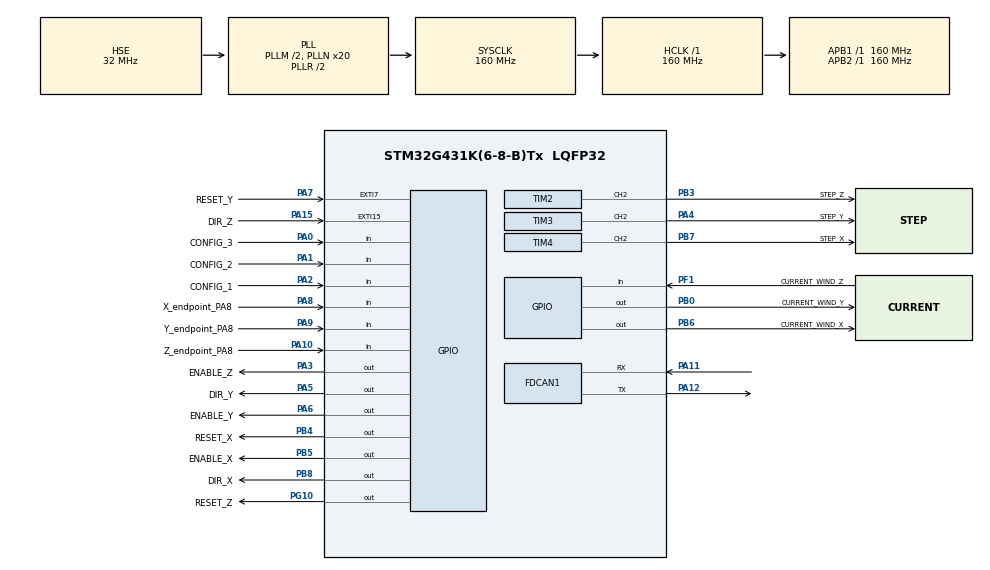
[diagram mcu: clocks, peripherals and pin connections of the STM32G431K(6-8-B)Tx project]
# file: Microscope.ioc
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FDCAN1.DataPrescaler=20
FDCAN1.DataSyncJumpWidth=3
FDCAN1.DataTimeSeg1=11
FDCAN1.DataTimeSeg2=14
FDCAN1.NominalPrescaler=20
FDCAN1.NominalSyncJumpWidth=3
FDCAN1.NominalTimeSeg1=11
FDCAN1.NominalTimeSeg2=4
Mcu.Family=STM32G4
Mcu.Name=STM32G431K(6-8-B)Tx
Mcu.Package=LQFP32
NVIC.EXTI15_10_IRQn=true\:0\:0\:false\:false\:true\:true\:true
NVIC.EXTI9_5_IRQn=true\:0\:0\:false\:false\:true\:true\:true
NVIC.FDCAN1_IT0_IRQn=true\:0\:0\:false\:false\:true\:true\:true
NVIC.PriorityGroup=NVIC_PRIORITYGROUP_4
NVIC.TIM1_UP_TIM16_IRQn=true\:0\:0\:false\:false\:true\:true\:true
NVIC.TIM2_IRQn=true\:0\:0\:false\:false\:true\:true\:true
NVIC.TIM3_IRQn=true\:0\:0\:false\:false\:true\:true\:true
NVIC.TIM4_IRQn=true\:0\:0\:false\:false\:true\:true\:true
NVIC.TIM7_IRQn=true\:0\:0\:false\:false\:true\:true\:true
PA0.GPIO_Label=CONFIG_3
PA0.GPIO_PuPd=GPIO_PULLDOWN
PA0.Signal=GPIO_Input
PA1.GPIO_Label=CONFIG_2
PA1.GPIO_PuPd=GPIO_PULLDOWN
PA1.Signal=GPIO_Input
PA10.GPIO_Label=Z_endpoint_PA8
PA10.Signal=GPIO_Input
PA11.Mode=FDCAN_Activate
PA11.Signal=FDCAN1_RX
PA12.Mode=FDCAN_Activate
PA12.Signal=FDCAN1_TX
PA13.Mode=Serial_Wire
PA13.Signal=SYS_JTMS-SWDIO
PA14.Mode=Serial_Wire
PA14.Signal=SYS_JTCK-SWCLK
PA15.GPIO_Label=DIR_Z
PA15.GPIO_ModeDefaultEXTI=GPIO_MODE_IT_RISING_FALLING
PA15.Signal=GPXTI15
PA2.GPIO_Label=CONFIG_1
PA2.GPIO_PuPd=GPIO_PULLDOWN
PA2.Signal=GPIO_Input
PA3.GPIO_Label=ENABLE_Z
PA3.PinState=GPIO_PIN_RESET
PA3.Signal=GPIO_Output
PA4.GPIO_Label=STEP_Y
PA4.Signal=S_TIM3_CH2
PA5.GPIO_Label=DIR_Y
PA5.PinState=GPIO_PIN_RESET
PA5.Signal=GPIO_Output
PA6.GPIO_Label=ENABLE_Y
PA6.PinState=GPIO_PIN_RESET
PA6.Signal=GPIO_Output
PA7.GPIO_Label=RESET_Y
PA7.GPIO_ModeDefaultEXTI=GPIO_MODE_IT_RISING_FALLING
PA7.Signal=GPXTI7
PA8.GPIO_Label=X_endpoint_PA8
PA8.Signal=GPIO_Input
PA9.GPIO_Label=Y_endpoint_PA8
PA9.Signal=GPIO_Input
PB0.GPIO_Label=CURRENT_WIND_Y
PB0.Signal=GPIO_Output
PB3.GPIO_Label=STEP_Z
PB3.Signal=S_TIM2_CH2
PB4.GPIO_Label=RESET_X
PB4.Signal=GPIO_Output
PB5.GPIO_Label=ENABLE_X
PB5.PinState=GPIO_PIN_RESET
PB5.Signal=GPIO_Output
PB6.GPIO_Label=CURRENT_WIND_X
PB6.Signal=GPIO_Output
PB7.GPIO_Label=STEP_X
PB7.Signal=S_TIM4_CH2
PB8-BOOT0.GPIO_Label=DIR_X
PB8-BOOT0.Signal=GPIO_Output
PF0-OSC_IN.Mode=HSE-External-Clock-Source
PF0-OSC_IN.Signal=RCC_OSC_IN
PF1-OSC_OUT.GPIO_Label=CURRENT_WIND_Z
PF1-OSC_OUT.Signal=GPIO_Input
PG10-NRST.GPIO_Label=RESET_Z
PG10-NRST.Signal=GPIO_Output
ProjectManager.HeapSize=0x2000
ProjectManager.StackSize=0x4000
ProjectManager.TargetToolchain=Makefile
RCC.ADC12Freq_Value=160000000
RCC.AHBFreq_Value=160000000
RCC.APB1Freq_Value=160000000
RCC.APB1TimFreq_Value=160000000
RCC.APB2Freq_Value=160000000
RCC.APB2TimFreq_Value=160000000
RCC.CortexFreq_Value=160000000
RCC.EXTERNAL_CLOCK_VALUE=12288000
RCC.HCLKFreq_Value=160000000
RCC.HSE_VALUE=32000000
RCC.HSI48_VALUE=48000000
RCC.HSI_VALUE=16000000
RCC.LSE_VALUE=32768
RCC.PLLM=RCC_PLLM_DIV2
RCC.PLLN=20
RCC.PLLSourceVirtual=RCC_PLLSOURCE_HSE
RCC.SYSCLKFreq_VALUE=160000000
RCC.SYSCLKSource=RCC_SYSCLKSOURCE_PLLCLK
RCC.USBFreq_Value=160000000
RCC.VCOOutputFreq_Value=320000000
SH.S_TIM2_CH2.0=TIM2_CH2,PWM Generation2 CH2
SH.S_TIM3_CH2.0=TIM3_CH2,PWM Generation2 CH2
SH.S_TIM4_CH2.0=TIM4_CH2,PWM Generation2 CH2
TIM1.AutoReloadPreload=TIM_AUTORELOAD_PRELOAD_DISABLE
TIM1.PeriodNoDither=1000-1
TIM1.Prescaler=160-1
TIM2.AutoReloadPreload=TIM_AUTORELOAD_PRELOAD_ENABLE
TIM2.Channel-PWM\ Generation2\ CH2=TIM_CHANNEL_2
TIM2.PeriodNoDither=1000-1
TIM2.Prescaler=160-1
TIM2.PulseNoDither_2=500-1
TIM3.AutoReloadPreload=TIM_AUTORELOAD_PRELOAD_ENABLE
TIM3.Channel-PWM\ Generation2\ CH2=TIM_CHANNEL_2
TIM3.PeriodNoDither=1000-1
TIM3.Prescaler=160-1
TIM3.PulseNoDither_2=500-1
TIM4.AutoReloadPreload=TIM_AUTORELOAD_PRELOAD_ENABLE
TIM4.Channel-PWM\ Generation2\ CH2=TIM_CHANNEL_2
TIM4.PeriodNoDither=1000-1
TIM4.Prescaler=160-1
TIM4.PulseNoDither_2=500-1
TIM6.PeriodNoDither=10000-1
TIM6.Prescaler=16000-1
TIM7.PeriodNoDither=13000-1
TIM7.Prescaler=16000-1
VP_SYS_VS_DBSignals.Mode=DisableDeadBatterySignals
VP_TIM1_VS_ClockSourceINT.Mode=Internal
VP_TIM2_VS_ClockSourceINT.Mode=Internal
VP_TIM3_VS_ClockSourceINT.Mode=Internal
VP_TIM4_VS_ClockSourceINT.Mode=Internal
VP_TIM6_VS_ClockSourceINT.Mode=Enable_Timer
VP_TIM7_VS_ClockSourceINT.Mode=Enable_Timer
VP_TIM7_VS_OPM.Mode=OPM_bit
board=custom

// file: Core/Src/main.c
/* USER CODE BEGIN Header */
/**
  ******************************************************************************
  * @file           : main.c
  * @brief          : Main program body
  ******************************************************************************
  * @attention
  *
  * <h2><center>&copy; Copyright (c) 2022 STMicroelectronics.
  * All rights reserved.</center></h2>
  *
  * This software component is licensed by ST under BSD 3-Clause license,
  * the "License"; You may not use this file except in compliance with the
  * License. You may obtain a copy of the License at:
  *                        opensource.org/licenses/BSD-3-Clause
  *
  ******************************************************************************
  */
/* USER CODE END Header */
#include "main.h"
#include "fdcan.h"
#include "tim.h"
#include "gpio.h"

void SystemClock_Config(void);
/* USER CODE BEGIN PFP */
extern void while_in_main_App();
extern void appInit();
/* USER CODE END PFP */

int main(void)
{

  /* MCU Configuration--------------------------------------------------------*/

  /* Reset of all peripherals, Initializes the Flash interface and the Systick. */
  HAL_Init();

  /* Configure the system clock */
  SystemClock_Config();

  /* Initialize all configured peripherals */
  MX_GPIO_Init();
  MX_FDCAN1_Init();
  MX_TIM1_Init();
  MX_TIM4_Init();
  MX_TIM3_Init();
  MX_TIM7_Init();
  MX_TIM6_Init();
  MX_TIM2_Init();
  /* USER CODE BEGIN 2 */
  appInit();
  /* USER CODE END 2 */
  /* Infinite loop */
  while (1)
  {
    /* USER CODE BEGIN 3 */
     while_in_main_App();
  }
  /* USER CODE END 3 */
}

void SystemClock_Config(void)
{
  RCC_OscInitTypeDef RCC_OscInitStruct = {0};
  RCC_ClkInitTypeDef RCC_ClkInitStruct = {0};
  RCC_PeriphCLKInitTypeDef PeriphClkInit = {0};

  /** Configure the main internal regulator output voltage
  */
  HAL_PWREx_ControlVoltageScaling(PWR_REGULATOR_VOLTAGE_SCALE1_BOOST);
  /** Initializes the RCC Oscillators according to the specified parameters
  * in the RCC_OscInitTypeDef structure.
  */
  RCC_OscInitStruct.OscillatorType = RCC_OSCILLATORTYPE_HSE;
  RCC_OscInitStruct.HSEState = RCC_HSE_BYPASS;
  RCC_OscInitStruct.PLL.PLLState = RCC_PLL_ON;
  RCC_OscInitStruct.PLL.PLLSource = RCC_PLLSOURCE_HSE;
  RCC_OscInitStruct.PLL.PLLM = RCC_PLLM_DIV2;
  RCC_OscInitStruct.PLL.PLLN = 20;
  RCC_OscInitStruct.PLL.PLLP = RCC_PLLP_DIV2;
  RCC_OscInitStruct.PLL.PLLQ = RCC_PLLQ_DIV2;
  RCC_OscInitStruct.PLL.PLLR = RCC_PLLR_DIV2;
  if (HAL_RCC_OscConfig(&RCC_OscInitStruct) != HAL_OK)
  {
    Error_Handler();
  }
  /** Initializes the CPU, AHB and APB buses clocks
  */
  RCC_ClkInitStruct.ClockType = RCC_CLOCKTYPE_HCLK|RCC_CLOCKTYPE_SYSCLK
                              |RCC_CLOCKTYPE_PCLK1|RCC_CLOCKTYPE_PCLK2;
  RCC_ClkInitStruct.SYSCLKSource = RCC_SYSCLKSOURCE_PLLCLK;
  RCC_ClkInitStruct.AHBCLKDivider = RCC_SYSCLK_DIV1;
  RCC_ClkInitStruct.APB1CLKDivider = RCC_HCLK_DIV1;
  RCC_ClkInitStruct.APB2CLKDivider = RCC_HCLK_DIV1;

  if (HAL_RCC_ClockConfig(&RCC_ClkInitStruct, FLASH_LATENCY_4) != HAL_OK)
  {
    Error_Handler();
  }
  /** Initializes the peripherals clocks
  */
  PeriphClkInit.PeriphClockSelection = RCC_PERIPHCLK_FDCAN;
  PeriphClkInit.FdcanClockSelection = RCC_FDCANCLKSOURCE_PCLK1;
  if (HAL_RCCEx_PeriphCLKConfig(&PeriphClkInit) != HAL_OK)
  {
    Error_Handler();
  }
}

void Error_Handler(void)
{
  /* USER CODE BEGIN Error_Handler_Debug */
  /* User can add his own implementation to report the HAL error return state */
  __disable_irq();
  while (1)
  {
      int x=0;
  }
  /* USER CODE END Error_Handler_Debug */
}

/************************ (C) COPYRIGHT STMicroelectronics *****END OF FILE****/
